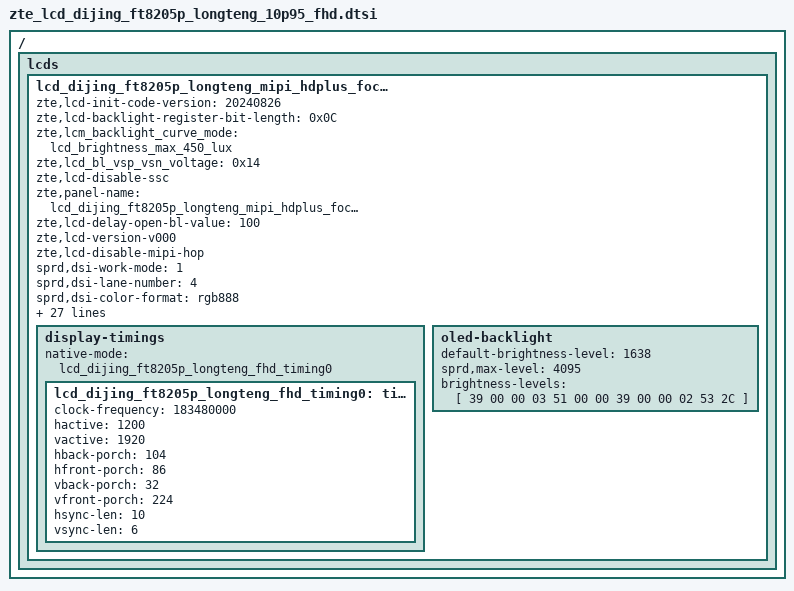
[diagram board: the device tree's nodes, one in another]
/ {
	fragment {
		target-path = "/";
		__overlay__ {
			lcds {
				lcd_dijing_ft8205p_longteng_mipi_hdplus_focal: lcd_dijing_ft8205p_longteng_mipi_hdplus_focal {
					zte,lcd-init-code-version = "20240826";

					zte,lcd-backlight-register-bit-length = <0x0C>;
					zte,lcm_backlight_curve_mode = "lcd_brightness_max_450_lux";
					zte,lcd_bl_vsp_vsn_voltage = <0x14>;
					zte,lcd-disable-ssc;
					zte,panel-name = "lcd_dijing_ft8205p_longteng_mipi_hdplus_focal";
					zte,lcd-delay-open-bl-value = <100>;
					zte,lcd-version-v000;
					zte,lcd-disable-mipi-hop;

					sprd,dsi-work-mode = <1>;
					sprd,dsi-lane-number = <4>;
					sprd,dsi-color-format = "rgb888";
					sprd,dpi-clk-div = <6>;
					sprd,video-lp-cmd-enable = <1>;
					sprd,hporch-lp-disable = <1>;
					sprd,slice-width = <600>;
					sprd,slice-height = <20>;
					sprd,output-bpc = <8>;
					sprd,dsc-enable = <0>;
					sprd,dual-dsi-enable = <0>;

					sprd,phy-bit-clock = <1100880>;
					sprd,phy-escape-clock = <20000>;/* kHz */

					sprd,width-mm = <147420>;
					sprd,height-mm = <235872>;

					sprd,esd-check-enable = <0>;/* 0:close , 1:open */
					sprd,esd-check-mode = <1>;/* 0:REG ,1:TE  */
					sprd,esd-check-period = <2000>;
					sprd,esd-check-register = <0x0A>;
					sprd,esd-check-value = <0x9C>;

					sprd,dphy-taget-val = <5>;

					sprd,reset-on-sequence = <1 5>, <0 2>, <1 55>;
					sprd,reset-off-sequence = <1 20>;

					sprd,use-gen-write;
					sprd,initial-command = [
						29 00 00 02 41 5A
						29 00 00 03 41 5A 08
						29 00 00 05 80 82 00 82 00
						29 00 00 03 41 5A 09
						29 00 00 11 80 1A 01 AB 93 A5 97 59 2A B1 06 00 00 80 BF 85 10
						29 00 00 11 90 42 44 84 14 C6 23 9A 11 C0 23 F4 D5 07 20 27 00
						29 00 00 11 A0 80 90 20 AA 00 04 55 55 05 00 1E 15 42 00 FE FF
						29 00 00 11 B0 03 7E F3 00 37 01 37 01 00 00 00 41 25 00 4A 00
						29 00 00 11 C0 00 00 00 00 00 00 00 00 12 04 02 00 07 00 08 18
						29 00 00 03 D0 00 00
						29 00 00 03 41 5A 0A
						29 00 00 11 80 91 91 D4 14 40 33 42 4D 57 67 74 75 81 81 95 6F
						29 00 00 11 90 5F 62 58 4F 43 32 27 20 0C 0B 0A 0E 40 33 42 4D
						29 00 00 11 A0 57 67 74 75 81 81 95 6F 5F 62 58 4F 43 32 27 20
						29 00 00 04 B0 0C 0B 0A
						29 00 00 03 41 5A 0B
						29 00 00 11 80 00 00 50 B5 C5 AC 00 00 A0 6A 8B A9 AE 22 02 00
						29 00 00 11 90 EF D8 B8 F7 25 70 E0 08 11 02 40 13 4F 4D 3C 35
						29 00 00 09 A0 F1 A4 06 FF FF 00 03 00
						29 00 00 03 41 5A 0C
						29 00 00 11 80 FE 68 58 02 BC 37 31 08 00 00 56 01 00 55 61 15
						29 00 00 11 90 55 51 15 56 01 00 56 01 00 55 61 15 55 51 15 56
						29 00 00 11 A0 B1 84 01 00 00 00 00 00 00 40 94 02 00 00 00 30
						29 00 00 11 B0 28 15 80 04 00 18 00 00 00 30 0A 00 00 00 00 00
						29 00 00 08 C0 00 01 05 C2 B0 00 00
						29 00 00 03 41 5A 0D
						29 00 00 11 80 08 00 00 28 02 00 04 12 00 08 02 77 02 4A 10 F0
						29 00 00 07 90 00 02 58 16 04 A1
						29 00 00 03 41 5A 0E
						29 00 00 11 80 FF 81 68 EC 26 FD 22 00 55 55 55 55 05 5A 5A 80
						29 00 00 07 90 01 00 00 60 01 00
						29 00 00 03 41 5A 0F
						29 00 00 11 80 13 39 C1 23 63 04 80 04 06 02 28 84 0B 00 70 03
						29 00 00 11 90 19 04 20 00 06 10 00 A0 05 5A 10 00 00 90 94 92
						29 00 00 11 A0 1D DC 41 B3 65 C0 4A 0B 5A 71 22 80 19 4A 00 20
						29 00 00 11 B0 27 9E 01 C0 19 7A 21 14 00 40 30 E0 00 2D D0 82
						29 00 00 11 C0 00 00 60 18 63 D0 A0 0D 9A 21 02 10 62 84 28 03
						29 00 00 11 D0 8A 88 88 48 92 09 0F 15 1E E0 31 06 04 02 14 04
						29 00 00 11 E0 10 22 22 BD 84 C8 41 24 10 51 2D 3E 64 40 40 00
						29 00 00 10 F0 00 DE 1A 04 F5 FF FF 3F 00 00 15 40 14 00 00
						29 00 00 03 41 5A 10
						29 00 00 11 80 00 00 03 E7 8F 0B 00 3C 80 01 6A 0C 18 C4 20 C5
						29 00 00 11 90 1C 94 D4 62 CD 3D F8 03 3F F0 03 3F 00 FF FF FF
						29 00 00 03 A0 81 00
						29 00 00 03 41 5A 11
						29 00 00 08 80 00 00 00 00 00 00 00
						29 00 00 03 41 5A 12
						29 00 00 11 80 00 00 00 00 00 00 00 00 00 00 00 00 00 00 00 01
						29 00 00 11 90 01 10 00 00 3C 3C FB FB 00 00 00 00 00 00 00 00
						29 00 00 11 A0 00 00 01 00 00 00 3C 3C FB FB 14 3C 3C FB FB 07
						29 00 00 08 B0 01 00 00 00 00 00 82
						29 00 00 03 41 5A 13
						29 00 00 11 80 00 08 80 15 00 90 10 18 3E 10 00 D6 03 04 18 00
						29 00 00 11 90 70 88 30 90 32 70 3E 97 8B 39 30 C4 09 C4 09 C4
						29 00 00 11 A0 89 4F B6 43 E0 09 C4 09 C4 09 E0 01 00 00 00 00
						29 00 00 11 B0 00 00 00 00 00 00 DB 01 31 75 B9 42 86 CA 31 75
						29 00 00 11 C0 B9 42 86 CA 00 00 00 00 0C 60 00 24 18 00 09 06
						29 00 00 11 D0 40 82 01 90 60 00 24 D0 01 09 74 40 02 1D 90 40
						29 00 00 11 E0 07 24 D0 01 09 1E 46 1E 46 00 00 20 C5 0F 00 C0
						29 00 00 0D F0 10 40 26 4E 46 02 C8 20 80 0C 00 00
						29 00 00 03 41 5A 14
						29 00 00 11 80 01 02 40 2C 99 DF EF F7 23 5F 03 00 00 C0 83 98
						29 00 00 11 90 40 BE 1A B0 11 C8 57 02 34 C0 EF 47 80 26 F8 FD
						29 00 00 11 A0 08 D0 0C BF 1F 01 9A E1 F7 23 00 80 07 00 00 00
						29 00 00 11 B0 00 00 00 00 00 00 00 00 00 00 00 00 80 87 07 87
						29 00 00 11 C0 07 05 00 30 18 0C CF 01 F2 95 04 C5 00 F4 0C 20
						29 00 00 11 D0 5F 49 50 0C 40 4F 00 F2 95 04 C5 00 F4 14 20 5F
						29 00 00 11 E0 49 50 0C 40 4F 02 F2 95 04 C5 00 F4 34 20 5F 49
						29 00 00 11 F0 50 0C 40 4F 04 F2 95 04 C5 00 F4 54 20 5F 49 50
						29 00 00 03 41 5A 15
						29 00 00 11 80 0C 40 41 80 DF 0F 00 00 00 00 00 00 00 00 00 00
						29 00 00 11 90 00 00 00 00 00 00 00 00 00 40 CA 03 0E 1E 0F 00
						29 00 00 11 A0 00 00 1C 00 00 00 08 42 60 0E 00 00 00 00 00 00
						29 00 00 11 B0 00 00 00 00 00 00 00 00 00 00 00 00 00 00 00 00
						29 00 00 11 C0 00 00 00 00 00 00 00 00 00 60 1B 00 D8 01 50 A6
						29 00 00 11 D0 C9 34 1D 47 51 0C 43 10 3C AF EB A2 A8 6D DB B6
						29 00 00 11 E0 6D DB B6 6D DB B6 6D DB B6 6D DB B6 6D DB B6 6D
						29 00 00 11 F0 DB B6 6D 25 C9 34 19 06 41 08 02 00 3C AF EB 20
						29 00 00 03 41 5A 16
						29 00 00 11 80 A8 6D DB B6 6D DB B6 6D DB B6 6D DB B6 6D DB B6
						29 00 00 11 90 6D DB B6 6D DB B6 6D 49 0A 0A 0A 0A 00 00 00 00
						29 00 00 11 A0 00 00 00 00 00 00 00 00 00 00 00 00 C0 1F E1 01
						29 00 00 11 B0 28 02 00 00 00 00 00 00 00 00 04 00 00 00 00 00
						29 00 00 11 C0 00 00 00 00 00 00 02 06 00 00 00 00 00 00 02 00
						29 00 00 11 D0 00 00 00 00 00 00 00 00 04 00 00 00 00 00 00 00
						29 00 00 11 E0 00 00 00 00 01 00 00 00 00 00 00 00 00 00 00 00
						29 00 00 11 F0 00 04 00 00 00 00 00 00 00 00 00 20 00 00 00 00
						29 00 00 03 41 5A 17
						29 00 00 11 80 00 00 00 00 00 04 00 00 00 00 00 00 00 00 00 20
						29 00 00 11 90 00 00 00 00 00 00 00 00 00 10 00 00 00 00 00 00
						29 00 00 11 A0 00 00 00 00 00 00 00 10 00 00 00 00 00 00 00 00
						29 00 00 11 B0 40 00 00 00 00 00 00 00 00 00 01 00 00 00 00 00
						29 00 00 11 C0 00 00 00 00 10 00 00 00 00 00 00 00 00 00 00 00
						29 00 00 07 D0 00 01 00 00 00 00
						29 00 00 03 41 5A 18
						29 00 00 11 80 7F 7F FE FE FE FE FE FE FE FE FE FE D4 7F D4 D4
						29 00 00 11 90 D4 D4 D4 D4 D4 D4 D4 D4 AA AA AA AA AA AA AA AA
						29 00 00 11 A0 AA AA AA AA 7F 7F 7F 7F 7F 7F 7F 7F 7F 7F 7F 7F
						29 00 00 11 B0 7C 83 79 86 79 86 79 86 79 86 79 86 7A 83 7A 85
						29 00 00 11 C0 7A 85 7A 85 7A 85 7A 85 7B 84 7B 84 7B 84 7B 84
						29 00 00 11 D0 7B 84 7B 84 7C 83 7C 83 7C 83 7C 83 7C 83 7C 83
						29 00 00 11 E0 FE 7F 7F FE FE FE FE FE FE FE FE FE FE D4 7F D4
						29 00 00 11 F0 D4 D4 D4 D4 D4 D4 D4 D4 D4 AA AA AA AA AA AA AA
						29 00 00 03 41 5A 19
						29 00 00 11 80 AA AA AA AA AA 7F 7F 7F 7F 7F 7F 7F 7F 7F 7F 7F
						29 00 00 11 90 7F 7C 83 79 86 79 86 79 86 79 86 79 86 7A 83 7A
						29 00 00 11 A0 85 7A 85 7A 85 7A 85 7A 85 7B 84 7B 84 7B 84 7B
						29 00 00 11 B0 84 7B 84 7B 84 7C 83 7C 83 7C 83 7C 83 7C 83 7C
						29 00 00 11 C0 83 7F 04 FF 1E 00 08 10 18 20 28 30 38 FC 00 04
						29 00 00 0C D0 20 00 01 08 40 00 02 10 80 00 FC
						29 00 00 03 41 5A 1A
						29 00 00 11 80 F0 D9 C8 BA AF A6 9E 98 92 8D 88 84 00 60 F6 CF
						29 00 00 11 90 FC 6F F6 EF CF AF 5F 55 00 F8 00 F8 00 F8 AD 8D
						29 00 00 11 A0 73 60 53 4A 43 7F 78 10 A0 3F 00 00 00 00 00 00
						29 00 00 11 B0 00 00 00 00 00 00 00 00 00 00 00 00 00 00 00 00
						29 00 00 09 C0 00 00 00 00 00 00 00 00
						29 00 00 03 41 5A 1C
						29 00 00 11 80 00 04 08 0C 00 10 14 18 1C 00 20 28 30 38 00 40
						29 00 00 11 90 48 50 58 00 60 68 70 78 00 80 88 90 98 00 A0 A8
						29 00 00 11 A0 B0 B8 00 C0 C8 D0 D8 00 E0 E8 F0 F8 00 FC FE FF
						29 00 00 11 B0 00 00 04 08 0C 00 10 14 18 1C 00 20 28 30 38 00
						29 00 00 11 C0 40 48 50 58 00 60 68 70 78 00 80 88 90 98 00 A0
						29 00 00 11 D0 A8 B0 B8 00 C0 C8 D0 D8 00 E0 E8 F0 F8 00 FC FE
						29 00 00 11 E0 FF 00 00 04 08 0C 00 10 14 18 1C 00 20 28 30 38
						29 00 00 11 F0 00 40 48 50 58 00 60 68 70 78 00 80 88 90 98 00
						29 00 00 03 41 5A 1D
						29 00 00 11 80 A0 A8 B0 B8 00 C0 C8 D0 D8 00 E0 E8 F0 F8 00 FC
						29 00 00 05 90 FE FF 00 00
						29 00 00 03 41 5A 1F
						29 00 00 11 80 5A 0F 70 09 28 30 38 40 48 50 58 60 20 30 38 40
						29 00 00 11 90 48 50 58 60 20 28 38 40 48 50 58 60 20 28 30 40
						29 00 00 11 A0 48 50 58 60 20 28 30 38 48 50 58 60 20 28 30 38
						29 00 00 11 B0 40 50 58 60 20 28 30 38 40 48 58 60 20 28 30 38
						29 00 00 11 C0 40 48 50 60 20 28 30 38 40 48 50 58 FF 5A 1E 20
						29 00 00 0D D0 00 02 20 00 02 20 00 02 20 00 02 FE
						29 00 00 03 41 5A 20
						29 00 00 11 80 44 73 03 00 CA F3 FF 6B 10 08 02 08 03 41 18 30
						29 00 00 11 90 18 44 E1 40 E1 20 30 18 C8 21 41 01 39 13 44 42
						29 00 00 11 A0 91 50 28 14 0A 85 03 D2 B0 80 36 7F D0 1F 12 E0
						29 00 00 11 B0 18 36 1B 11 04 20 02 D0 80 B3 21 38 20 18 88 03
						29 00 00 11 C0 82 01 4D 70 40 30 8D 0D A4 A2 00 80 04 38 00 50
						29 00 00 11 D0 80 13 E0 00 14 C0 70 40 00 E0 81 00 00 28 0E 06
						29 00 00 11 E0 43 55 55 55 55 55 D5 CC CC CC CC CC 4C 08 82 C6
						29 00 00 11 F0 E0 01 00 00 00 21 42 88 00 00 00 00 00 00 00 20
						29 00 00 03 41 5A 21
						29 00 00 11 80 04 41 06 49 90 04 49 00 00 49 00 00 49 00 00 49
						29 00 00 11 90 90 04 00 85 11 0C 00 00 40 00 00 00 00 16 00 A5
						29 00 00 11 A0 00 08 08 15 10 D1 B6 45 92 8A 20 A2 6D 0B 00 54
						29 00 00 11 B0 40 44 DB 16 00 48 92 24 09 E0 0F 80 55 30 01 10
						29 00 00 11 C0 01 42 82 11 20 02 10 10 01 08 88 00 04 44 00 02
						29 00 00 11 D0 22 00 04 91 80 1F 00 40 40 04 00 00 00 18 10 16
						29 00 00 03 E0 10 00
						29 00 00 03 41 5A 22
						29 00 00 11 80 29 D3 00 55 55 55 55 55 55 55 55 55 55 55 1F 70
						29 00 00 04 90 F0 00 00
						29 00 00 03 41 5A 23
						29 00 00 11 80 09 01 02 05 00 05 04 00 00 00 00 00 00 00 00 00
						29 00 00 0A 90 00 FF 1F 20 00 01 00 00 FE
						29 00 00 03 41 5A 24
						29 00 00 11 80 00 03 00 FF FF 66 00 00 00 00 00 00 00 00 95 57
						29 00 00 0F 90 5A A5 5A 00 00 00 00 22 22 3A 22 00 00 00
						29 00 00 03 41 5A 24
						29 00 00 02 90 A5
						29 00 00 03 41 5A 13
						29 00 00 02 B6 DB
						29 00 00 03 41 5A 2F
						29 00 00 02 4C 03
						29 00 00 02 09 00
						29 00 00 03 51 00 00
						29 00 00 02 35 00
						29 00 00 02 53 24
						29 00 00 02 55 00
						05 78 00 01 11
						05 0A 00 01 29
					];

					sprd,sleep-in-command = [
						15 01 00 02 AC 0A
						39 14 00 03 28 00 00
						39 78 00 03 10 00 00
						];
					sprd,sleep-out-command = [
						05 78 00 01 11
						05 14 00 01 29
						];
					display-timings {
						native-mode = <&lcd_dijing_ft8205p_longteng_fhd_timing0>;
						lcd_dijing_ft8205p_longteng_fhd_timing0: timing0 {
							clock-frequency = <183480000>;
							hactive = <1200>;
							vactive = <1920>;
							hback-porch = <104>;
							hfront-porch = <86>;
							vback-porch = <32>;
							vfront-porch = <224>;
							hsync-len = <10>;
							vsync-len = <6>;
						};
					};
					oled-backlight {
						default-brightness-level = <1638>;
						sprd,max-level = <4095>;
						brightness-levels = [
							39 00 00 03 51 00 00
							39 00 00 02 53 2C
						];
					};
				};
			};
		};
	};
};
